# WKUP_CBASS0_QOS register map
Vendor: Texas Instruments
Peripheral module from a debugger description file (folder J7_AHP).
Registers are 32-bit, read-write, reset 0x7000 unless marked. A register's access mark holds for its fields unless they carry their own. Offsets are as the file gives them; lines under a group give offsets from that group; [hi:lo] are bit positions; {n}, {i} and the like mark numbered series; 'fields as' and 'values as' point back to an identical list; <NAME> marks a mode.

## WKUP_CBASS0_QOS
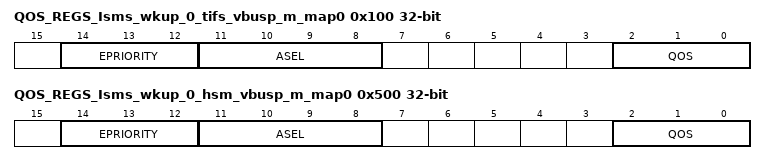
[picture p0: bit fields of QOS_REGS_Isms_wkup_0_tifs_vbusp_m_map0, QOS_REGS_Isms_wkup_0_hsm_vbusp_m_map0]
0x100 QOS_REGS_Isms_wkup_0_tifs_vbusp_m_map0
  [14:12] EPRIORITY — epriority signal for channel N.
  [11:8] ASEL — asel signal for channel N. 0 = SOC address. 1-15 = peripheral address.
  [2:0] QOS — qos signal for channel N.
0x500 QOS_REGS_Isms_wkup_0_hsm_vbusp_m_map0
  fields as QOS_REGS_Isms_wkup_0_tifs_vbusp_m_map0
